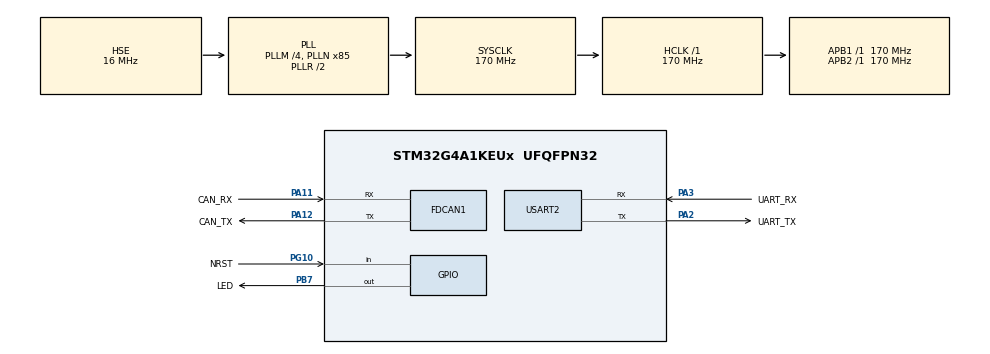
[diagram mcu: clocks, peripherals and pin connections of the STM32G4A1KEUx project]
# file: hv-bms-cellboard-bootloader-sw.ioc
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FDCAN1.CalculateBaudRateNominal=1000000
FDCAN1.CalculateTimeBitNominal=1000
FDCAN1.CalculateTimeQuantumNominal=62.5
FDCAN1.DataPrescaler=1
FDCAN1.DataTimeSeg1=7
FDCAN1.DataTimeSeg2=8
FDCAN1.NominalPrescaler=1
FDCAN1.NominalTimeSeg1=11
FDCAN1.NominalTimeSeg2=4
FDCAN1.StdFiltersNbr=1
Mcu.Family=STM32G4
Mcu.Name=STM32G4A1KEUx
Mcu.Package=UFQFPN32
NVIC.FDCAN1_IT0_IRQn=true\:0\:0\:false\:false\:true\:true\:true\:true
NVIC.FDCAN1_IT1_IRQn=true\:0\:0\:false\:false\:true\:true\:true\:true
NVIC.PriorityGroup=NVIC_PRIORITYGROUP_4
NVIC.TIM7_IRQn=true\:15\:0\:false\:false\:true\:false\:true\:true
NVIC.TimeBase=TIM7_IRQn
NVIC.TimeBaseIP=TIM7
PA11.GPIO_Label=CAN_RX
PA11.Mode=FDCAN_Activate
PA11.Signal=FDCAN1_RX
PA12.GPIO_Label=CAN_TX
PA12.Mode=FDCAN_Activate
PA12.Signal=FDCAN1_TX
PA13.Mode=Serial_Wire
PA13.Signal=SYS_JTMS-SWDIO
PA14.Mode=Serial_Wire
PA14.Signal=SYS_JTCK-SWCLK
PA2.GPIO_Label=UART_TX
PA2.Mode=Asynchronous
PA2.Signal=USART2_TX
PA3.GPIO_Label=UART_RX
PA3.Mode=Asynchronous
PA3.Signal=USART2_RX
PB7.GPIO_Label=LED
PB7.Signal=GPIO_Output
PF0-OSC_IN.Mode=HSE-External-Oscillator
PF0-OSC_IN.Signal=RCC_OSC_IN
PF1-OSC_OUT.Mode=HSE-External-Oscillator
PF1-OSC_OUT.Signal=RCC_OSC_OUT
PG10-NRST.GPIO_Label=NRST
PG10-NRST.GPIO_PuPd=GPIO_PULLUP
PG10-NRST.Signal=GPIO_Input
ProjectManager.HeapSize=0x200
ProjectManager.StackSize=0x400
ProjectManager.TargetToolchain=Makefile
RCC.ADC12Freq_Value=170000000
RCC.ADC345Freq_Value=170000000
RCC.AHBFreq_Value=170000000
RCC.APB1Freq_Value=170000000
RCC.APB1TimFreq_Value=170000000
RCC.APB2Freq_Value=170000000
RCC.APB2TimFreq_Value=170000000
RCC.CortexFreq_Value=170000000
RCC.EXTERNAL_CLOCK_VALUE=12288000
RCC.FDCANCLockSelection=RCC_FDCANCLKSOURCE_HSE
RCC.HCLKFreq_Value=170000000
RCC.HSE_VALUE=16000000
RCC.HSI48_VALUE=48000000
RCC.HSI_VALUE=16000000
RCC.LSE_VALUE=32768
RCC.PLLM=RCC_PLLM_DIV4
RCC.PLLN=85
RCC.PLLQ=RCC_PLLQ_DIV8
RCC.PLLSourceVirtual=RCC_PLLSOURCE_HSE
RCC.SYSCLKFreq_VALUE=170000000
RCC.SYSCLKSource=RCC_SYSCLKSOURCE_PLLCLK
RCC.USBFreq_Value=48000000
RCC.VCOOutputFreq_Value=340000000
USART2.VirtualMode-Asynchronous=VM_ASYNC
VP_SYS_VS_DBSignals.Mode=DisableDeadBatterySignals
VP_SYS_VS_tim7.Mode=TIM7
board=custom

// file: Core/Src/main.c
/* USER CODE BEGIN Header */
/**
  ******************************************************************************
  * @file           : main.c
  * @brief          : Main program body
  ******************************************************************************
  * @attention
  *
  * Copyright (c) 2024 STMicroelectronics.
  * All rights reserved.
  *
  * This software is licensed under terms that can be found in the LICENSE file
  * in the root directory of this software component.
  * If no LICENSE file comes with this software, it is provided AS-IS.
  *
  ******************************************************************************
  */
/* USER CODE END Header */
#include "main.h"
#include "fdcan.h"
#include "usart.h"
#include "gpio.h"

/* USER CODE BEGIN Includes */
#include "boot.h"
#include "flash.h"
/* USER CODE END Includes */

void SystemClock_Config(void);

int main(void)
{

  /* MCU Configuration--------------------------------------------------------*/

  /* Reset of all peripherals, Initializes the Flash interface and the Systick. */
  HAL_Init();

  /* Configure the system clock */
  SystemClock_Config();

  /* Initialize all configured peripherals */
  MX_GPIO_Init();
  MX_FDCAN1_Init();
  MX_USART2_UART_Init();
  /* USER CODE BEGIN 2 */
  BootInit();
  HAL_FDCAN_Start(&HCAN_BMS);

  // HAL_FLASH_Unlock();
  // __HAL_FLASH_CLEAR_FLAG(FLASH_FLAG_OPTVERR);
  // FLASH_EraseInitTypeDef init = {
  //   .TypeErase = FLASH_TYPEERASE_PAGES,
  //   .Banks = FLASH_BANK_1,
  //   .Page = 6,
  //   .NbPages = 1
  // };
  // uint32_t page_error = 0U;
  // if (HAL_FLASHEx_Erase(&init, &page_error) != HAL_OK)
  //     Error_Handler();
  // HAL_FLASH_Lock();
  /* USER CODE END 2 */

  /* Infinite loop */
  /* USER CODE BEGIN WHILE */
  uint32_t t = 0U;
  while (1)
  {
    BootTask();

    if (HAL_GetTick() - t >= 500) {
        // const FDCAN_TxHeaderTypeDef header = {
        //     .Identifier = 911,
        //     .IdType = FDCAN_STANDARD_ID,
        //     .TxFrameType = FDCAN_DATA_FRAME,
        //     .DataLength = 2,
        //     .ErrorStateIndicator = FDCAN_ESI_ACTIVE,
        //     .BitRateSwitch = FDCAN_BRS_OFF,
        //     .FDFormat = FDCAN_CLASSIC_CAN,
        //     .TxEventFifoControl = FDCAN_STORE_TX_EVENTS,
        //     .MessageMarker = 0U
        // };
        // uint8_t data[2] = { 9, 11 };
        // HAL_FDCAN_AddMessageToTxFifoQ(&hfdcan1, &header, data);
        HAL_GPIO_TogglePin(LED_GPIO_Port, LED_Pin);
        t = HAL_GetTick();
    }
    /* USER CODE END WHILE */

  }
}

void SystemClock_Config(void)
{
  RCC_OscInitTypeDef RCC_OscInitStruct = {0};
  RCC_ClkInitTypeDef RCC_ClkInitStruct = {0};

  /** Configure the main internal regulator output voltage
  */
  HAL_PWREx_ControlVoltageScaling(PWR_REGULATOR_VOLTAGE_SCALE1_BOOST);

  /** Initializes the RCC Oscillators according to the specified parameters
  * in the RCC_OscInitTypeDef structure.
  */
  RCC_OscInitStruct.OscillatorType = RCC_OSCILLATORTYPE_HSE;
  RCC_OscInitStruct.HSEState = RCC_HSE_ON;
  RCC_OscInitStruct.PLL.PLLState = RCC_PLL_ON;
  RCC_OscInitStruct.PLL.PLLSource = RCC_PLLSOURCE_HSE;
  RCC_OscInitStruct.PLL.PLLM = RCC_PLLM_DIV4;
  RCC_OscInitStruct.PLL.PLLN = 85;
  RCC_OscInitStruct.PLL.PLLP = RCC_PLLP_DIV2;
  RCC_OscInitStruct.PLL.PLLQ = RCC_PLLQ_DIV8;
  RCC_OscInitStruct.PLL.PLLR = RCC_PLLR_DIV2;
  if (HAL_RCC_OscConfig(&RCC_OscInitStruct) != HAL_OK)
  {
    Error_Handler();
  }

  /** Initializes the CPU, AHB and APB buses clocks
  */
  RCC_ClkInitStruct.ClockType = RCC_CLOCKTYPE_HCLK|RCC_CLOCKTYPE_SYSCLK
                              |RCC_CLOCKTYPE_PCLK1|RCC_CLOCKTYPE_PCLK2;
  RCC_ClkInitStruct.SYSCLKSource = RCC_SYSCLKSOURCE_PLLCLK;
  RCC_ClkInitStruct.AHBCLKDivider = RCC_SYSCLK_DIV1;
  RCC_ClkInitStruct.APB1CLKDivider = RCC_HCLK_DIV1;
  RCC_ClkInitStruct.APB2CLKDivider = RCC_HCLK_DIV1;

  if (HAL_RCC_ClockConfig(&RCC_ClkInitStruct, FLASH_LATENCY_4) != HAL_OK)
  {
    Error_Handler();
  }
}

void HAL_TIM_PeriodElapsedCallback(TIM_HandleTypeDef *htim)
{
  if (htim->Instance == TIM7) {
    HAL_IncTick();
  }
}

void Error_Handler(void)
{
  __disable_irq();
  while (1)
  {
  }
}
